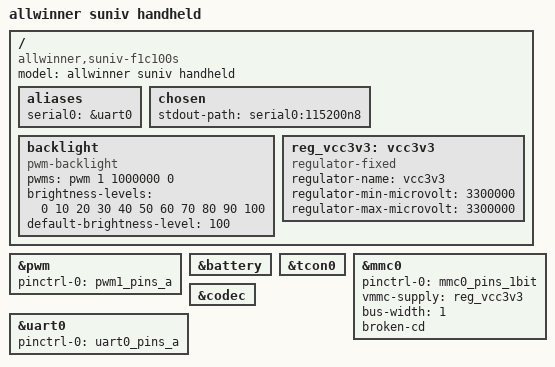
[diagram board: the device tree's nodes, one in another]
// SPDX-License-Identifier: (GPL-2.0+ OR X11)
/*
 * Copyright 2018 Icenowy Zheng <icenowy@aosc.io>
 * Copyright 2021 Steward Fu <steward.fu@gmail.com>
 */

/dts-v1/;
#include "suniv.dtsi"
#include <dt-bindings/gpio/gpio.h>

/ {
  model = "allwinner suniv handheld";
  compatible = "allwinner,suniv-f1c100s";

  aliases {
    serial0 = &uart0;
  };

  chosen {
    stdout-path = "serial0:115200n8";
  };
   
  backlight {
    compatible = "pwm-backlight";
    pwms = <&pwm 1 1000000 0>;
    brightness-levels = <0 10 20 30 40 50 60 70 80 90 100>;
    default-brightness-level = <100>;
    status = "okay";
  };

  reg_vcc3v3: vcc3v3 {
    compatible = "regulator-fixed";
    regulator-name = "vcc3v3";
    regulator-min-microvolt = <3300000>;
    regulator-max-microvolt = <3300000>;
  };
};

&pwm {
  pinctrl-names = "default";
  pinctrl-0 = <&pwm1_pins_a>;
  status = "okay";
};

&battery {
  status = "okay";
};

&tcon0 {
  status = "okay";
};

&mmc0 {
  pinctrl-names = "default";
  pinctrl-0 = <&mmc0_pins_1bit>;
  vmmc-supply = <&reg_vcc3v3>;
  bus-width = <1>;
  broken-cd;
  status = "okay";
};

&codec {
  status = "okay";
};

&uart0 {
  pinctrl-names = "default";
  pinctrl-0 = <&uart0_pins_a>;
  status = "okay";
};

